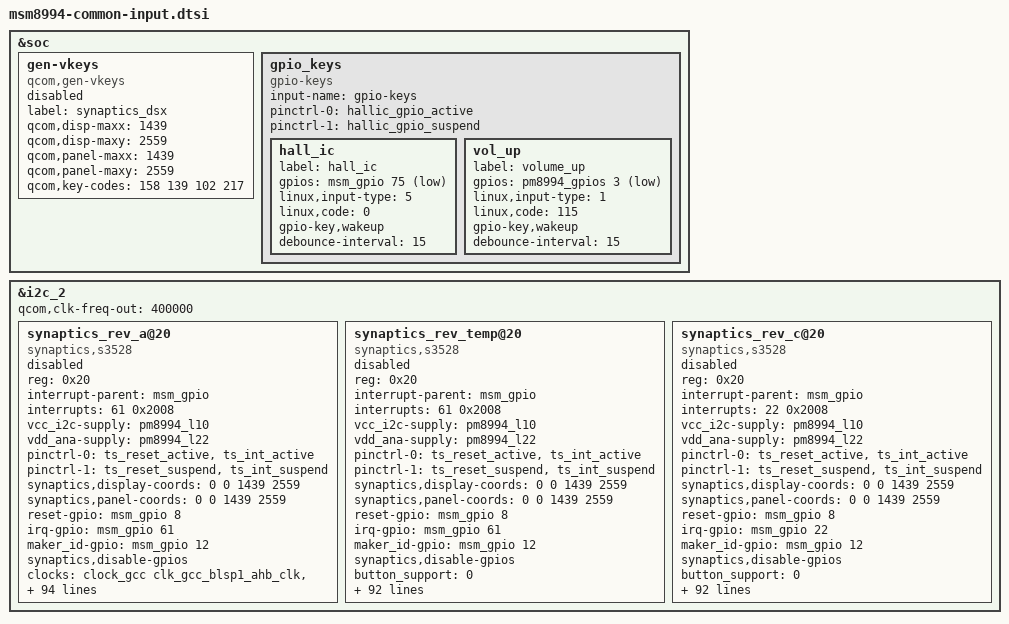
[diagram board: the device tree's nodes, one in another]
/* Copyright (c) 2014, The Linux Foundation. All rights reserved.
 *
 * This program is free software; you can redistribute it and/or modify
 * it under the terms of the GNU General Public License version 2 and
 * only version 2 as published by the Free Software Foundation.
 *
 * This program is distributed in the hope that it will be useful,
 * but WITHOUT ANY WARRANTY; without even the implied warranty of
 * MERCHANTABILITY or FITNESS FOR A PARTICULAR PURPOSE.  See the
 * GNU General Public License for more details.
 */

&soc {
	gen-vkeys {
		status = "diabled";
		compatible = "qcom,gen-vkeys";
		label = "synaptics_dsx";
		qcom,disp-maxx = <1439>;
		qcom,disp-maxy = <2559>;
		qcom,panel-maxx = <1439>;
		qcom,panel-maxy = <2559>;
		qcom,key-codes = <158 139 102 217>;
	};

	gpio_keys {
		compatible = "gpio-keys";
		input-name = "gpio-keys";

		pinctrl-names = "tlmm_gpio_key_active","tlmm_gpio_key_suspend";
		pinctrl-0 = <&hallic_gpio_active>;
		pinctrl-1 = <&hallic_gpio_suspend>;

		hall_ic {
			label = "hall_ic";
			gpios = <&msm_gpio 75 0x1>;
			linux,input-type = <5>;
			linux,code = <0>;
			gpio-key,wakeup;
			debounce-interval = <15>;
		};

		vol_up {
			label = "volume_up";
			gpios = <&pm8994_gpios 3 0x1>;
			linux,input-type = <1>;
			linux,code = <115>;
			gpio-key,wakeup;
			debounce-interval = <15>;
		};
	};
};

&i2c_2 {
	qcom,clk-freq-out = <400000>;
	synaptics_rev_a@20 {
		status = "disable";
		compatible = "synaptics,s3528";
		reg = <0x20>;
		interrupt-parent = <&msm_gpio>;
		interrupts = <61 0x2008>;
		vcc_i2c-supply = <&pm8994_l10>;
		vdd_ana-supply = <&pm8994_l22>;
		pinctrl-names = "pmx_ts_active", "pmx_ts_suspend";
		pinctrl-0 = <&ts_reset_active &ts_int_active>;
		pinctrl-1 = <&ts_reset_suspend &ts_int_suspend>;
		synaptics,display-coords = <0 0 1439 2559>;
		synaptics,panel-coords = <0 0 1439 2559>;
		reset-gpio = <&msm_gpio 8 0x00>;
		irq-gpio = <&msm_gpio 61 0x2008>;
		maker_id-gpio = <&msm_gpio 12 0x00>;
		synaptics,disable-gpios;
		/* Underlying clocks used by secure touch */
		clock-names = "iface_clk", "core_clk";
		clocks = <&clock_gcc clk_gcc_blsp1_ahb_clk>,
			 <&clock_gcc clk_gcc_blsp1_qup2_i2c_apps_clk>;

		/*Caps*/
		button_support = <0>;
		number_of_button = <4>;
		button_name = [9e 8b 66 d9];
		max_x = <1439>;
		max_y = <2559>;
		max_pressure = <0xff>;
		max_width = <15>;
		max_orientation = <1>;
		max_id = <10>;

		/*role*/
		protocol_type = <1>;
		report_mode = <0>;
		delta_pos_threshold = <1>;
		report_period = <10000000>;
		booting_delay = <80>;
		reset_delay = <10>;
		wake_up_by_touch = <1>;
		use_sleep_mode = <1>;
		thermal_check = <1>;
		palm_ctrl_mode = <0>;
		use_hover_finger = <0>;
		use_rmi_dev = <1>;
		irqflags = <0x00000002>;
		bouncing.enable = <0>;
		grip.enable = <0>;
		grip.edge_region = <5>;
		grip.max_delta = <10>;
		grip.width_ratio = <2>;
		accuracy.enable = <0>;
		accuracy.min_delta = <3>;
		accuracy.curr_ratio = <5>;
		accuracy.min_pressure = <50>;
		jitter.enable = <0>;
		jitter.curr_ratio = <115>;
		quickcover.enable = <1>;
		quickcover.X1 = <148>;
		quickcover.X2 = <1292>;
		quickcover.Y1 = <0>;
		quickcover.Y2 = <1101>;
		crack.enable = <0>;
		crack.min.cap = <300>;

		/*ghost_detection -S*/
		ghost_detection_enable = <0>;
		ghost_detection_chk_cnt = <3>;
		jitter_value = <20>;
		ta_noise_chk = <0>;
		incoming_call_chk = <0>;
		first_finger_chk = <1>;
		first_finger_time = <200>;
		pressure_zero_chk = <1>;
		ta_debouncing_chk = <0>;
		ta_debouncing_cnt = <2>;
		ta_debouncing_finger_num = <2>;
		press_interval_chk = <1>;
		press_interval = <29>;
		diff_fingers_chk = <1>;
		diff_finger_num = <5>;
		subtraction_finger_chk = <0>;
		subtraction_time = <11>;
		subtraction_finger_cnt = <5>;
		long_press_chk = <1>;
		long_press_chk_time = <10>;
		long_press_cnt = <700>;
		button_chk = <0>;
		button_int_num = <6>;
		button_duration = <100>;
		rebase_repetition_chk = <1>;
		rebase_since_init = <3>;
		rebase_since_rebase = <5>;
		use_lpwg_all = <1>;
		use_security_mode = <0>;
		use_lcd_notifier_callback = <1>;
		/*ghost_detection -E*/

		/*pwr*/
		use_regulator = <0>;
		vdd = "vdd_ana";
		vdd_voltage = <3000000>;
		vio = "vcc_i2c";
		vio_voltage = <1800000>;
		vio_control = <0>;
		reset_control = <3>;

		/*firmware*/
		need_upgrade = <1>;
		fw_pid_addr = <0x0040 0x0040 0x0000 0x4e4>;     /*PLG446_BL6, PLG468_BL6, PLG446_BL7, PLG468_BL7*/
		fw_ver_addr = <0x16d00 0x15500 0x0000 0x4e0>;    /*PLG446_BL6, PLG468_BL6, PLG446_BL7, PLG468_BL7*/

		/* Rx & Tx cap*/
		tx_cap = <5 10 2 9 7 5 1 2 2 1 10 2 3 83 7 2 8 0 10 0 5 8 4 8 6 40 88>;
		rx_cap = <53 12 15 26 28 13 27 25 4 15 5 6 22 9 44>;
		/* 1:sd. 2:ref_rebase. 3:TX. 4:RX.*/
		ref_chk_option = <0 0 1 1>;

		/* firmware & panel_spec path */
		fw_image = "synaptics/g4/PLG446-V1.05-PR1800278-DS5.2.13.1014_40055185.img",    /*PLG446_BL6*/
			   "synaptics/g4/PLG468-V1.05-PR1801483-DS5.2.100.0.1005_50055185.img",             /*PLG468_BL6*/
                           "synaptics/g4/JDI_Official_BL7.img",                                             /*PLG446_BL7*/
			   "synaptics/g4/PLG468-V1.06-PR1801488-DS5.2.200.0.1010_50055186504C47343638.img"; /*PLG468_BL7*/
		panel_spec = "synaptics/g4/g4_limit.txt";
		panel_spec_mfts = "synaptics/g4/g4_limit_mfts.txt";
	};

	/* synaptics_rev_temp is used for only 'g4_kr' with revision A (Ti DSV) */
	synaptics_rev_temp@20 {
		status = "disable";
		compatible = "synaptics,s3528";
		reg = <0x20>;
		interrupt-parent = <&msm_gpio>;
		interrupts = <61 0x2008>;
		vcc_i2c-supply = <&pm8994_l10>;
		vdd_ana-supply = <&pm8994_l22>;
		pinctrl-names = "pmx_ts_active", "pmx_ts_suspend";
		pinctrl-0 = <&ts_reset_active &ts_int_active>;
		pinctrl-1 = <&ts_reset_suspend &ts_int_suspend>;
		synaptics,display-coords = <0 0 1439 2559>;
		synaptics,panel-coords = <0 0 1439 2559>;
		reset-gpio = <&msm_gpio 8 0x00>;
		irq-gpio = <&msm_gpio 61 0x2008>;
		maker_id-gpio = <&msm_gpio 12 0x00>;
		synaptics,disable-gpios;

		/*Caps*/
		button_support = <0>;
		number_of_button = <4>;
		button_name = [9e 8b 66 d9];
		max_x = <1439>;
		max_y = <2559>;
		max_pressure = <0xff>;
		max_width = <15>;
		max_orientation = <1>;
		max_id = <10>;

		/*role*/
		protocol_type = <1>;
		report_mode = <0>;
		delta_pos_threshold = <1>;
		report_period = <10000000>;
		booting_delay = <80>;
		reset_delay = <10>;
		wake_up_by_touch = <1>;
		use_sleep_mode = <1>;
		thermal_check = <1>;
		palm_ctrl_mode = <0>;
		use_hover_finger = <0>;
		use_rmi_dev = <1>;
		irqflags = <0x00000002>;
		bouncing.enable = <0>;
		grip.enable = <0>;
		grip.edge_region = <5>;
		grip.max_delta = <10>;
		grip.width_ratio = <2>;
		accuracy.enable = <0>;
		accuracy.min_delta = <3>;
		accuracy.curr_ratio = <5>;
		accuracy.min_pressure = <50>;
		jitter.enable = <0>;
		jitter.curr_ratio = <115>;
		quickcover.enable = <1>;
		quickcover.X1 = <148>;
		quickcover.X2 = <1292>;
		quickcover.Y1 = <0>;
		quickcover.Y2 = <1101>;
		crack.enable = <0>;
		crack.min.cap = <300>;

		/*ghost_detection -S*/
		ghost_detection_enable = <0>;
		ghost_detection_chk_cnt = <3>;
		jitter_value = <20>;
		ta_noise_chk = <0>;
		incoming_call_chk = <0>;
		first_finger_chk = <1>;
		first_finger_time = <200>;
		pressure_zero_chk = <1>;
		ta_debouncing_chk = <0>;
		ta_debouncing_cnt = <2>;
		ta_debouncing_finger_num = <2>;
		press_interval_chk = <1>;
		press_interval = <29>;
		diff_fingers_chk = <1>;
		diff_finger_num = <5>;
		subtraction_finger_chk = <0>;
		subtraction_time = <11>;
		subtraction_finger_cnt = <5>;
		long_press_chk = <1>;
		long_press_chk_time = <10>;
		long_press_cnt = <700>;
		button_chk = <0>;
		button_int_num = <6>;
		button_duration = <100>;
		rebase_repetition_chk = <1>;
		rebase_since_init = <3>;
		rebase_since_rebase = <5>;
		use_lpwg_all = <1>;
		use_security_mode = <0>;
		use_lcd_notifier_callback = <1>;
		/*ghost_detection -E*/

		/*pwr*/
		use_regulator = <0>;
		vdd = "vdd_ana";
		vdd_voltage = <3000000>;
		vio = "vcc_i2c";
		vio_voltage = <1800000>;
		vio_control = <0>;
		reset_control = <3>;

		/*firmware*/
		need_upgrade = <1>;
		fw_pid_addr = <0x0040 0x0040 0x0000 0x4e4>;     /*PLG446_BL6, PLG468_BL6, PLG446_BL7, PLG468_BL7*/
		fw_ver_addr = <0x16d00 0x15500 0x0000 0x4e0>;    /*PLG446_BL6, PLG468_BL6, PLG446_BL7, PLG468_BL7*/

		/* Rx & Tx cap*/
		tx_cap = <5 10 2 9 7 5 1 2 2 1 10 2 3 83 7 2 8 0 10 0 5 8 4 8 6 40 88>;
		rx_cap = <53 12 15 26 28 13 27 25 4 15 5 6 22 9 44>;
		/* 1:sd. 2:ref_rebase. 3:TX. 4:RX.*/
		ref_chk_option = <0 0 1 1>;

		/* firmware & panel_spec path */
		fw_image = "synaptics/g4/PLG446-V1.05-PR1800278-DS5.2.13.1014_40055185.img",    /*PLG446_BL6*/
			   "synaptics/g4/PLG468-V1.05-PR1801483-DS5.2.100.0.1005_50055185.img",             /*PLG468_BL6*/
                           "synaptics/g4/JDI_Official_BL7.img",                                             /*PLG446_BL7*/
			   "synaptics/g4/PLG468-V1.06-PR1801488-DS5.2.200.0.1010_50055186504C47343638.img"; /*PLG468_BL7*/
		panel_spec = "synaptics/g4/g4_limit.txt";
		panel_spec_mfts = "synaptics/g4/g4_limit_mfts.txt";
	};

	/* synaptics_rev_b is the same with synaptics_rev_a. */
	/* It is used for only 'g4_kr' with revision C or more. */
	synaptics_rev_c@20 {
		status = "disable";
		compatible = "synaptics,s3528";
		reg = <0x20>;
		interrupt-parent = <&msm_gpio>;
		interrupts = <22 0x2008>;
		vcc_i2c-supply = <&pm8994_l10>;
		vdd_ana-supply = <&pm8994_l22>;
		pinctrl-names = "pmx_ts_active", "pmx_ts_suspend";
		pinctrl-0 = <&ts_reset_active &ts_int_active>;
		pinctrl-1 = <&ts_reset_suspend &ts_int_suspend>;
		synaptics,display-coords = <0 0 1439 2559>;
		synaptics,panel-coords = <0 0 1439 2559>;
		reset-gpio = <&msm_gpio 8 0x00>;
		irq-gpio = <&msm_gpio 22 0x2008>;
		maker_id-gpio = <&msm_gpio 12 0x00>;
		synaptics,disable-gpios;

		/*Caps*/
		button_support = <0>;
		number_of_button = <4>;
		button_name = [9e 8b 66 d9];
		max_x = <1439>;
		max_y = <2559>;
		max_pressure = <0xff>;
		max_width = <15>;
		max_orientation = <1>;
		max_id = <10>;

		/*role*/
		protocol_type = <1>;
		report_mode = <0>;
		delta_pos_threshold = <1>;
		report_period = <10000000>;
		booting_delay = <80>;
		reset_delay = <10>;
		wake_up_by_touch = <1>;
		use_sleep_mode = <1>;
		thermal_check = <1>;
		palm_ctrl_mode = <0>;
		use_hover_finger = <0>;
		use_rmi_dev = <1>;
		irqflags = <0x00000002>;
		bouncing.enable = <0>;
		grip.enable = <0>;
		grip.edge_region = <5>;
		grip.max_delta = <10>;
		grip.width_ratio = <2>;
		accuracy.enable = <0>;
		accuracy.min_delta = <3>;
		accuracy.curr_ratio = <5>;
		accuracy.min_pressure = <50>;
		jitter.enable = <0>;
		jitter.curr_ratio = <115>;
		quickcover.enable = <1>;
		quickcover.X1 = <148>;
		quickcover.X2 = <1292>;
		quickcover.Y1 = <0>;
		quickcover.Y2 = <1101>;
		crack.enable = <0>;
		crack.min.cap = <300>;

		/*ghost_detection -S*/
		ghost_detection_enable = <0>;
		ghost_detection_chk_cnt = <3>;
		jitter_value = <20>;
		ta_noise_chk = <0>;
		incoming_call_chk = <0>;
		first_finger_chk = <1>;
		first_finger_time = <200>;
		pressure_zero_chk = <1>;
		ta_debouncing_chk = <0>;
		ta_debouncing_cnt = <2>;
		ta_debouncing_finger_num = <2>;
		press_interval_chk = <1>;
		press_interval = <29>;
		diff_fingers_chk = <1>;
		diff_finger_num = <5>;
		subtraction_finger_chk = <0>;
		subtraction_time = <11>;
		subtraction_finger_cnt = <5>;
		long_press_chk = <1>;
		long_press_chk_time = <10>;
		long_press_cnt = <700>;
		button_chk = <0>;
		button_int_num = <6>;
		button_duration = <100>;
		rebase_repetition_chk = <1>;
		rebase_since_init = <3>;
		rebase_since_rebase = <5>;
		use_lpwg_all = <1>;
		use_security_mode = <0>;
		use_lcd_notifier_callback = <1>;
		/*ghost_detection -E*/

		/*pwr*/
		use_regulator = <0>;
		vdd = "vdd_ana";
		vdd_voltage = <3000000>;
		vio = "vcc_i2c";
		vio_voltage = <1800000>;
		vio_control = <0>;
		reset_control = <3>;

		/*firmware*/
		need_upgrade = <1>;
		fw_pid_addr = <0x0040 0x0040 0x0000 0x4e4>;     /*PLG446_BL6, PLG468_BL6, PLG446_BL7, PLG468_BL7*/
		fw_ver_addr = <0x16d00 0x15500 0x0000 0x4e0>;    /*PLG446_BL6, PLG468_BL6, PLG446_BL7, PLG468_BL7*/

		/* Rx & Tx cap*/
		tx_cap = <5 10 2 9 7 5 1 2 2 1 10 2 3 83 7 2 8 0 10 0 5 8 4 8 6 40 88>;
		rx_cap = <53 12 15 26 28 13 27 25 4 15 5 6 22 9 44>;

		/* 1:sd. 2:ref_rebase. 3:TX. 4:RX.*/
		ref_chk_option = <0 0 1 1>;

		/* firmware & panel_spec path */
		fw_image = "synaptics/g4/PLG446-V1.05-PR1800278-DS5.2.13.1014_40055185.img",    /*PLG446_BL6*/
			   "synaptics/g4/PLG468-V1.05-PR1801483-DS5.2.100.0.1005_50055185.img",             /*PLG468_BL6*/
                           "synaptics/g4/JDI_Official_BL7.img",                                             /*PLG446_BL7*/
			   "synaptics/g4/PLG468-V1.06-PR1801488-DS5.2.200.0.1010_50055186504C47343638.img"; /*PLG468_BL7*/
		panel_spec = "synaptics/g4/g4_limit.txt";
		panel_spec_mfts = "synaptics/g4/g4_limit_mfts.txt";
	};
};
